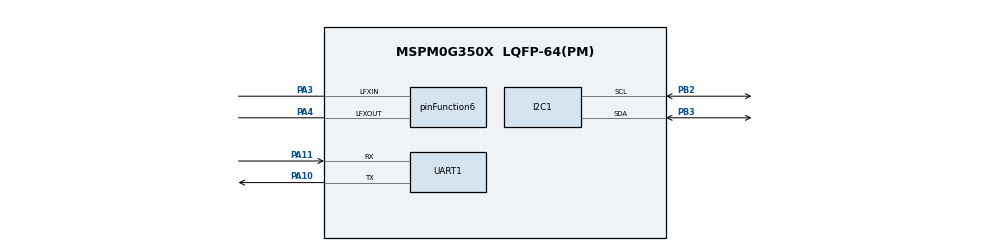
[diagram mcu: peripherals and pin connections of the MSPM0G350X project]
/**
 * @cliArgs --device "MSPM0G350X" --part "Default" --package "LQFP-64(PM)" --product "mspm0_sdk@2.02.00.05"
 * @versions {"tool":"1.21.2+3837"}
 */

/**
 * Import the modules used in this configuration.
 */
const GPIO          = scripting.addModule("/ti/driverlib/GPIO", {}, false);
const GPIO1         = GPIO.addInstance();
const I2C           = scripting.addModule("/ti/driverlib/I2C", {}, false);
const I2C1          = I2C.addInstance();
const SYSCTL        = scripting.addModule("/ti/driverlib/SYSCTL");
const TIMER         = scripting.addModule("/ti/driverlib/TIMER", {}, false);
const TIMER1        = TIMER.addInstance();
const UART          = scripting.addModule("/ti/driverlib/UART", {}, false);
const UART1         = UART.addInstance();
const ProjectConfig = scripting.addModule("/ti/project_config/ProjectConfig");

/**
 * Write custom configuration values to the imported modules.
 */
const gate7  = system.clockTree["MFCLKGATE"];
gate7.enable = true;

const mux5       = system.clockTree["EXLFMUX"];
mux5.inputSelect = "EXLFMUX_XTAL";

const mux9       = system.clockTree["LFXTMUX"];
mux9.inputSelect = "LFXTMUX_TRUE";

const pinFunction5     = system.clockTree["LFCLKEXT"];
pinFunction5.inputFreq = 32.768;

const pinFunction6                        = system.clockTree["LFXT"];
pinFunction6.enable                       = true;
pinFunction6.inputFreq                    = 32.768;
pinFunction6.peripheral.$assign           = "SYSCTL";
pinFunction6.peripheral.lfxInPin.$assign  = "PA3";
pinFunction6.peripheral.lfxOutPin.$assign = "PA4";

GPIO1.$name                          = "GPIO_LED";
GPIO1.associatedPins[0].$name        = "USER_LED_2B";
GPIO1.associatedPins[0].assignedPort = "PORTB";
GPIO1.associatedPins[0].assignedPin  = "22";

const Board = scripting.addModule("/ti/driverlib/Board", {}, false);

I2C1.$name                     = "I2C_0";
I2C1.basicEnableController     = true;
I2C1.advControllerTXFIFOTRIG   = "BYTES_1";
I2C1.intController             = ["NACK"];
I2C1.interruptPriority         = "3";
I2C1.peripheral.$assign        = "I2C1";
I2C1.peripheral.sdaPin.$assign = "PB3";
I2C1.peripheral.sclPin.$assign = "PB2";
I2C1.sdaPinConfig.$name        = "ti_driverlib_gpio_GPIOPinGeneric2";
I2C1.sclPinConfig.$name        = "ti_driverlib_gpio_GPIOPinGeneric3";

SYSCTL.forceDefaultClkConfig = true;
SYSCTL.MFCLKEn               = true;
SYSCTL.LFCLKSource           = "LFXT";
SYSCTL.clockTreeEn           = true;

TIMER1.$name             = "TIMER";
TIMER1.timerMode         = "PERIODIC";
TIMER1.interrupts        = ["ZERO"];
TIMER1.interruptPriority = "0";
TIMER1.timerClkSrc       = "LFCLK";
TIMER1.timerClkDiv       = 8;
TIMER1.timerPeriod       = "500 ms";

UART1.$name                       = "UART_0";
UART1.targetBaudRate              = 115200;
UART1.enableFIFO                  = true;
UART1.enabledInterrupts           = ["DMA_DONE_RX"];
UART1.enabledDMARXTriggers        = "DL_UART_DMA_INTERRUPT_RX";
UART1.rxFifoThreshold             = "DL_UART_RX_FIFO_LEVEL_ONE_ENTRY";
UART1.interruptPriority           = "1";
UART1.peripheral.$assign          = "UART0";
UART1.peripheral.rxPin.$assign    = "PA11";
UART1.peripheral.txPin.$assign    = "PA10";
UART1.txPinConfig.$name           = "ti_driverlib_gpio_GPIOPinGeneric0";
UART1.rxPinConfig.$name           = "ti_driverlib_gpio_GPIOPinGeneric1";
UART1.DMA_CHANNEL_RX.$name        = "DMA_CH0";
UART1.DMA_CHANNEL_RX.srcLength    = "BYTE";
UART1.DMA_CHANNEL_RX.dstLength    = "BYTE";
UART1.DMA_CHANNEL_RX.transferSize = 8;
UART1.DMA_CHANNEL_RX.addressMode  = "f2b";
UART1.DMA_CHANNEL_RX.transferMode = "FULL_CH_REPEAT_SINGLE";

ProjectConfig.genLibIQ = true;

/**
 * Pinmux solution for unlocked pins/peripherals. This ensures that minor changes to the automatic solver in a future
 * version of the tool will not impact the pinmux you originally saw.  These lines can be completely deleted in order to
 * re-solve from scratch.
 */
GPIO1.associatedPins[0].pin.$suggestSolution     = "PB22";
Board.peripheral.$suggestSolution                = "DEBUGSS";
Board.peripheral.swclkPin.$suggestSolution       = "PA20";
Board.peripheral.swdioPin.$suggestSolution       = "PA19";
TIMER1.peripheral.$suggestSolution               = "TIMA0";
UART1.DMA_CHANNEL_RX.peripheral.$suggestSolution = "DMA_CH0";
